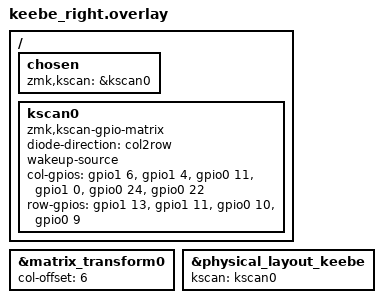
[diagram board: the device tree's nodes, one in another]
// This file was generated from a template. Edit it to match your keyboard.
// See https://zmk.dev/docs/development/hardware-integration/new-shield for more
// instructions.

#include "keebe.dtsi"

/ {
    chosen {
        zmk,kscan = &kscan0;
    };
};

/ {
    kscan0: kscan0 {
        compatible = "zmk,kscan-gpio-matrix";
        diode-direction = "col2row";
        wakeup-source;

        col-gpios
            = <&gpio1 6 GPIO_ACTIVE_HIGH>
            , <&gpio1 4 GPIO_ACTIVE_HIGH>
            , <&gpio0 11 GPIO_ACTIVE_HIGH>
            , <&gpio1 0 GPIO_ACTIVE_HIGH>
            , <&gpio0 24 GPIO_ACTIVE_HIGH>
            , <&gpio0 22 GPIO_ACTIVE_HIGH>
            ;

        row-gpios
            = <&gpio1 13 (GPIO_ACTIVE_HIGH | GPIO_PULL_DOWN)>
            , <&gpio1 11 (GPIO_ACTIVE_HIGH | GPIO_PULL_DOWN)>
            , <&gpio0 10 (GPIO_ACTIVE_HIGH | GPIO_PULL_DOWN)>
            , <&gpio0 9 (GPIO_ACTIVE_HIGH | GPIO_PULL_DOWN)>
            ;
    };
};

&matrix_transform0 {
    col-offset = <6>;
};

&physical_layout_keebe {
    kscan = <&kscan0>;
};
